# daric register map
Vendor: cramium
Registers are 32-bit, read-write, reset 0x0 unless marked. A register's access mark holds for its fields unless they carry their own. Offsets are from the block's base; [hi:lo] are bit positions.

## PKE
Base 0x4002C000
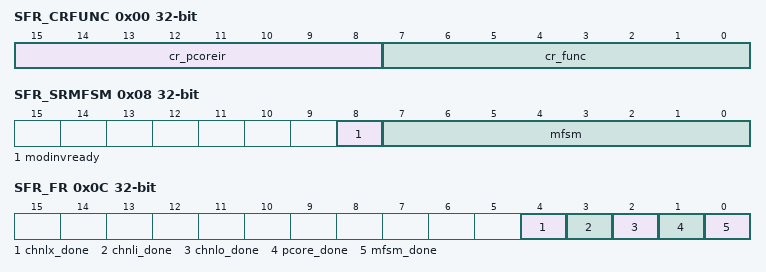
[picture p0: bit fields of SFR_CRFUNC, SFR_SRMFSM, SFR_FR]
0x00 SFR_CRFUNC — See file:///F:/code/cram-nto/modules/crypto_top/rtl/pke.sv
  [15:8] cr_pcoreir — cr_pcoreir read/write control register
  [7:0] cr_func — cr_func read/write control register
0x04 SFR_AR — See file:///F:/code/cram-nto/modules/crypto_top/rtl/pke.sv
  [31:0] sfr_ar — sfr_ar performs action on write of value: 0x5a
0x08 SFR_SRMFSM — See file:///F:/code/cram-nto/modules/crypto_top/rtl/pke.sv
  [8] modinvready — modinvready read only status register
  [7:0] mfsm — mfsm read only status register
0x0C SFR_FR — See file:///F:/code/cram-nto/modules/crypto_top/rtl/pke.sv
  [4] chnlx_done — chnlx_done flag register. `1` means event happened, write back `1` in respective bit position to clear the flag
  [3] chnli_done — chnli_done flag register. `1` means event happened, write back `1` in respective bit position to clear the flag
  [2] chnlo_done — chnlo_done flag register. `1` means event happened, write back `1` in respective bit position to clear the flag
  [1] pcore_done — pcore_done flag register. `1` means event happened, write back `1` in respective bit position to clear the flag
  [0] mfsm_done — mfsm_done flag register. `1` means event happened, write back `1` in respective bit position to clear the flag
0x10 SFR_OPTNW — See file:///F:/code/cram-nto/modules/crypto_top/rtl/pke.sv
  [13:0] sfr_optnw — sfr_optnw read/write control register
0x14 SFR_OPTEW — See file:///F:/code/cram-nto/modules/crypto_top/rtl/pke.sv
  [13:0] sfr_optew — sfr_optew read/write control register
0x18 SFR_OPTRW — See file:///F:/code/cram-nto/modules/crypto_top/rtl/pke.sv
  [9:0] sfr_optrw — sfr_optrw read/write control register
0x1C SFR_OPTLTX — See file:///F:/code/cram-nto/modules/crypto_top/rtl/pke.sv
  [4:0] sfr_optltx — sfr_optltx read/write control register
0x20 SFR_OPTMASK — See file:///F:/code/cram-nto/modules/crypto_top/rtl/pke.sv
  [15:0] sfr_optmask — sfr_optmask read/write control register
0x24 SFR_MIMMCR — See file:///F:/code/cram-nto/modules/crypto_top/rtl/pke.sv
  [8:0] sfr_mimmcr — sfr_mimmcr read/write control register
0x30 SFR_SEGPTR_PTRID_PCON — See file:///F:/code/cram-nto/modules/crypto_top/rtl/pke.sv
  [11:0] PTRID_PCON — cr_segptrstart read/write control register
0x34 SFR_SEGPTR_PTRID_PIB0 — See file:///F:/code/cram-nto/modules/crypto_top/rtl/pke.sv
  [11:0] PTRID_PIB0 — cr_segptrstart read/write control register
0x38 SFR_SEGPTR_PTRID_PIB1 — See file:///F:/code/cram-nto/modules/crypto_top/rtl/pke.sv
  [11:0] PTRID_PIB1 — cr_segptrstart read/write control register
0x3C SFR_SEGPTR_PTRID_PKB — See file:///F:/code/cram-nto/modules/crypto_top/rtl/pke.sv
  [11:0] PTRID_PKB — cr_segptrstart read/write control register
0x40 SFR_SEGPTR_PTRID_POB — See file:///F:/code/cram-nto/modules/crypto_top/rtl/pke.sv
  [11:0] PTRID_POB — cr_segptrstart read/write control register
0x50 SFR_TICKCYC — See file:///F:/code/cram-nto/modules/crypto_top/rtl/pke.sv
  [7:0] sfr_tickcyc — sfr_tickcyc read/write control register
0x54 SFR_TICKCNT — See file:///F:/code/cram-nto/modules/crypto_top/rtl/pke.sv
  [31:0] sfr_tickcnt — sfr_tickcnt read only status register
0x60 SFR_MASKSEED — See file:///F:/code/cram-nto/modules/crypto_top/rtl/pke.sv
  [31:0] sfr_maskseed — sfr_maskseed read/write control register
0x64 SFR_MASKSEEDAR — See file:///F:/code/cram-nto/modules/crypto_top/rtl/pke.sv
  [31:0] sfr_maskseedar — sfr_maskseedar performs action on write of value: 0x5a

## TRNG
Base 0x4002E000
0x00 SFR_CRSRC — See file:///F:/code/cram-nto/modules/crypto_top/rtl/trng.sv
  [11:0] sfr_crsrc — sfr_crsrc read/write control register
0x04 SFR_CRANA — See file:///F:/code/cram-nto/modules/crypto_top/rtl/trng.sv
  [15:0] sfr_crana — sfr_crana read/write control register
0x08 SFR_PP — See file:///F:/code/cram-nto/modules/crypto_top/rtl/trng.sv
  [16:0] sfr_pp — sfr_pp read/write control register
0x0C SFR_OPT — See file:///F:/code/cram-nto/modules/crypto_top/rtl/trng.sv
  [16:0] sfr_opt — sfr_opt read/write control register
0x10 SFR_SR — See file:///F:/code/cram-nto/modules/crypto_top/rtl/trng.sv
  [31:0] sr_rng — sr_rng read only status register
0x14 SFR_AR_GEN — See file:///F:/code/cram-nto/modules/crypto_top/rtl/trng.sv
  [31:0] sfr_ar_gen — sfr_ar_gen performs action on write of value: 0x55
0x18 SFR_FR — See file:///F:/code/cram-nto/modules/crypto_top/rtl/trng.sv
  [1:0] sfr_fr — sfr_fr flag register. `1` means event happened, write back `1` in respective bit position to clear the flag
0x20 SFR_DRPSZ — See file:///F:/code/cram-nto/modules/crypto_top/rtl/trng.sv
  [31:0] sfr_drpsz — sfr_drpsz read/write control register
0x24 SFR_DRGEN — See file:///F:/code/cram-nto/modules/crypto_top/rtl/trng.sv
  [31:0] sfr_drgen — sfr_drgen read/write control register
0x28 SFR_DRRESEED — See file:///F:/code/cram-nto/modules/crypto_top/rtl/trng.sv
  [31:0] sfr_drreseed — sfr_drreseed read/write control register
0x30 SFR_BUF — See file:///F:/code/cram-nto/modules/crypto_top/rtl/trng.sv
  [31:0] sfr_buf — sfr_buf read only status register
0x40 SFR_CHAIN_RNGCHAINEN0 — See file:///F:/code/cram-nto/modules/crypto_top/rtl/trng.sv
  [31:0] rngchainen0 — sfr_chain read/write control register
0x44 SFR_CHAIN_RNGCHAINEN1 — See file:///F:/code/cram-nto/modules/crypto_top/rtl/trng.sv
  [31:0] rngchainen1 — sfr_chain read/write control register
